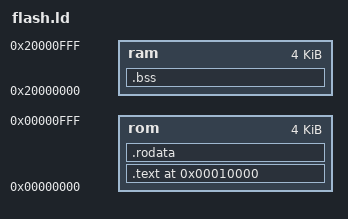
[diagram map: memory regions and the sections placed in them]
ENTRY(_start)

MEMORY
{
    rom : ORIGIN = 0x00000000, LENGTH = 0x1000
    ram : ORIGIN = 0x20000000, LENGTH = 0x1000
}

SECTIONS
{
    . = 0x10000;
    .text : { *(.text*) } > rom
    .rodata : { *(.rodata*) } > rom
    .bss : { *(.bss*) } > ram
}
